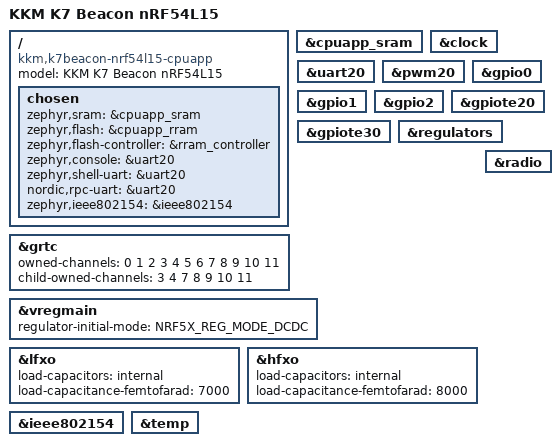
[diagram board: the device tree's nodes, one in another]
/*
 * Copyright (c) 2026
 * SPDX-License-Identifier: Apache-2.0
 */

/dts-v1/;
#include <nordic/nrf54l15_cpuapp.dtsi>
#include "k7beacon_nrf54l15_common.dtsi"

/ {
	model = "KKM K7 Beacon nRF54L15";
	compatible = "kkm,k7beacon-nrf54l15-cpuapp";

	chosen {
		zephyr,sram = &cpuapp_sram;
		zephyr,flash = &cpuapp_rram;
		zephyr,flash-controller = &rram_controller;
		zephyr,console = &uart20;
		zephyr,shell-uart = &uart20;
		nordic,rpc-uart = &uart20;
		zephyr,ieee802154 = &ieee802154;
	};
};

&cpuapp_sram {
	status = "okay";
};

&grtc {
	owned-channels = <0 1 2 3 4 5 6 7 8 9 10 11>;
	/* Channels 7-11 reserved for Zero Latency IRQs, 3-4 for FLPR */
	child-owned-channels = <3 4 7 8 9 10 11>;
	status = "okay";
};

&clock {
	status = "okay";
};

&uart20 {
	status = "okay";
};

&pwm20 {
	status = "okay";
};

&gpio0 {
	status = "okay";
};

&gpio1 {
	status = "okay";
};

&gpio2 {
	status = "okay";
};

&gpiote20 {
	status = "okay";
};

&gpiote30 {
	status = "okay";
};

&regulators {
	status = "okay";
};

&vregmain {
	status = "okay";
	regulator-initial-mode = <NRF5X_REG_MODE_DCDC>;
};

/*
 * Crystal load capacitors. The K7 fits a 32.768 kHz (CL 7 pF) LFXO and a
 * 32 MHz (CL 8 pF) HFXO with no discrete load caps, so the SoC internal
 * load caps are matched to each crystal's spec.
 */
&lfxo {
	load-capacitors = "internal";
	load-capacitance-femtofarad = <7000>;
	status = "okay";
};

&hfxo {
	load-capacitors = "internal";
	load-capacitance-femtofarad = <8000>;
	status = "okay";
};

&ieee802154 {
	status = "okay";
};

&temp {
	status = "okay";
};

&radio {
	status = "okay";
};

/*
 * No MCUboot / fixed-partition table is defined: the application links to the
 * base of cpuapp_rram and boots directly after a J-Link flash. Add a
 * partition map here later if you adopt MCUboot / DFU.
 */
